# NUC400_v1 register map
File version: 1.0
Registers are 32-bit, read-write, reset 0x0 unless marked. A register's access mark holds for its fields unless they carry their own. Offsets are from the block's base; [hi:lo] are bit positions; {n}, {i} and the like mark numbered series; 'fields as' and 'values as' point back to an identical list.

## CRYP — CRYPTO Register Map
Base 0x50080000
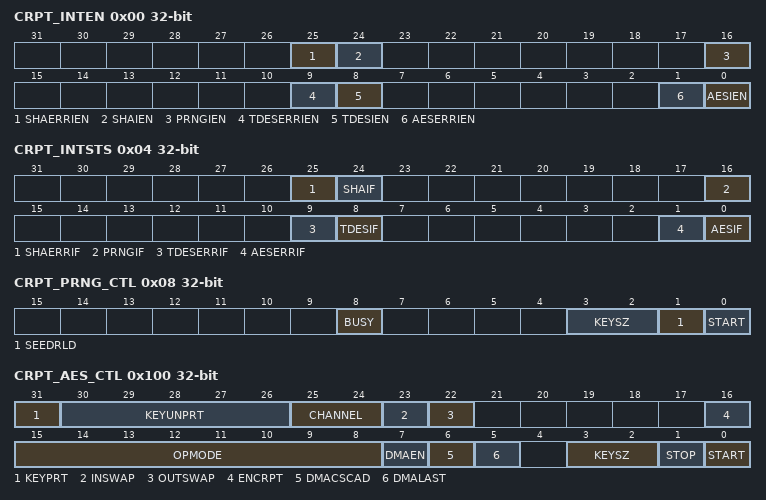
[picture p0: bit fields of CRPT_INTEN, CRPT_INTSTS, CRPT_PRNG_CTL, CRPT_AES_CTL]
0x00 CRPT_INTEN — Crypto Interrupt Enable Control Register
  [25] SHAERRIEN — SHA Error Interrupt Enable Bit
    0=SHA error interrupt flag Disabled; 1=SHA error interrupt flag Enabled
  [24] SHAIEN — SHA Interrupt Enable Bit. In DMA mode, an interrupt will be triggered when amount of data set in SHA _DMA_CNT is fed into the SHA engine. In Non-DMA mode, an interrupt will be triggered when the SHA engine finishes the operation.
    0=SHA interrupt Disabled; 1=SHA interrupt Enabled
  [16] PRNGIEN — PRNG Interrupt Enable Bit
    0=PRNG interrupt Disabled; 1=PRNG interrupt Enabled
  [9] TDESERRIEN — TDES/DES Error Flag Enable Bit
    0=TDES/DES error interrupt flag Disabled; 1=TDES/DES error interrupt flag Enabled
  [8] TDESIEN — TDES/DES Interrupt Enable Bit. In DMA mode, an interrupt will be triggered when amount of data set in TDES_DMA_CNT is fed into the TDES engine. In Non-DMA mode, an interrupt will be triggered when the TDES engine finishes the operation.
    0=TDES/DES interrupt Disabled; 1=TDES/DES interrupt Enabled
  [1] AESERRIEN — AES Error Flag Enable Bit
    0=AES error interrupt flag Disabled; 1=AES error interrupt flag Enabled
  [0] AESIEN — AES Interrupt Enable Bit. In DMA mode, an interrupt will be triggered when amount of data set in AES_DMA_CNT is fed into the AES engine. In Non-DMA mode, an interrupt will be triggered when the AES engine finishes the operation.
    0=AES interrupt Disabled; 1=AES interrupt Enabled
0x04 CRPT_INTSTS — Crypto Interrupt Flag
  [25] SHAERRIF — SHA Error Flag. This register includes operating and setting error. The detail flag is shown in SHA _FLAG register. This bit is cleared by writing 1, and it has no effect by writing 0.
    0=No SHA error; 1=SHA error interrupt
  [24] SHAIF — SHA Finish Interrupt Flag. This bit is cleared by writing 1, and it has no effect by writing 0.
    0=No SHA interrupt; 1=SHA operation done interrupt
  [16] PRNGIF — PRNG Finish Interrupt Flag. This bit is cleared by writing 1, and it has no effect by writing 0.
    0=No PRNG interrupt; 1=PRNG key generation done interrupt
  [9] TDESERRIF — TDES/DES Error Flag. This bit includes the operating and setting error. The detailed flag is shown in the TDES _FLAG register. This includes operating and setting error. This bit is cleared by writing 1, and it has no effect by writing 0.
    0=No TDES/DES error; 1=TDES/DES encryption/decryption error interrupt
  [8] TDESIF — TDES/DES Finish Interrupt Flag. This bit is cleared by writing 1, and it has no effect by writing 0.
    0=No TDES/DES interrupt; 1=TDES/DES encryption/decryption done interrupt
  [1] AESERRIF — AES Error Flag. This bit is cleared by writing 1, and it has no effect by writing 0.
    0=No AES error; 1=AES encryption/decryption done interrupt
  [0] AESIF — AES Finish Interrupt Flag. This bit is cleared by writing 1, and it has no effect by writing 0.
    0=No AES interrupt; 1=AES encryption/decryption done interrupt
0x08 CRPT_PRNG_CTL — PRNG Control Register
  [8] BUSY ro — PRNG Busy (Read Only)
    0=PRNG engine is idle; 1=Indicate that the PRNG engine is generating CRPT_PRNG_KEYx
  [3:2] KEYSZ — PRNG Generate Key Size
    0=64 bits; 1=128 bits; 2=192 bits; 3=256 bits
  [1] SEEDRLD — Reload New Seed For PRNG Engine
    0=Generating key based on the current seed; 1=Reload new seed
  [0] START — Start PRNG Engine
    0=Stop PRNG engine; 1=Generate new key and store the new key to register CRPT_PRNG_KEYx , which will be cleared when the new key is generated
0x0C CRPT_PRNG_SEED wo reset not defined — Seed for PRNG
  [31:0] SEED — Seed For PRNG (Write Only). The bits store the seed for PRNG engine.
{0x10+4i} CRPT_PRNG_KEY{i} ro reset not defined (i=0..7) — PRNG Generated Key{i}
  [31:0] KEYx — Store PRNG Generated Key (Read Only). The bits store the key that is generated by PRNG.
{0x50+4i} CRPT_AES_FDBCK{i} ro (i=0..3) — AES Engine Output Feedback Data After Cryptographic Operation
  [31:0] FDBCK — AES Feedback Information. The feedback value is 128 bits in size. The AES engine uses the data from CRPT_AES_FDBCKx as the data inputted to CRPT_AESn_IVx for the next block in DMA cascade mode. The AES engine outputs feedback information for IV in the next block's operation. Software can use this feedback information to implement more than four DMA channels. Software can store that feedback value temporarily. After switching back, fill the stored feedback value to this register in the same channel operation, and then continue the operation with the original setting.
0x60 CRPT_TDES_FDBCKH ro — TDES/DES Engine Output Feedback High Word Data After Cryptographic Operation
  [31:0] FDBCK — TDES/DES Feedback. The feedback value is 64 bits in size. The TDES/DES engine uses the data from {CRPT_TDES_FDBCKH, CRPT_TDES_FDBCKL} as the data inputted to {CRPT_TDESn_IVH, CRPT_TDESn_IVL} for the next block in DMA cascade mode. The feedback register is for CBC, CFB, and OFB mode. TDES/DES engine outputs feedback information for IV in the next block's operation. Software can use this feedback information to implement more than four DMA channels. Software can store that feedback value temporarily. After switching back, fill the stored feedback value to this register in the same channel operation. Then can continue the operation with the original setting.
0x64 CRPT_TDES_FDBCKL ro — TDES/DES Engine Output Feedback Low Word Data After Cryptographic Operation
  fields as CRPT_TDES_FDBCKH
0x100 CRPT_AES_CTL — AES Control Register
  [31] KEYPRT — Protect Key. Read as a flag to reflect KEYPRT.
    0=No effect; 1=Protect the content of the AES key from reading. The return value for reading CRPT_AESn_KEYx is not the content of the registers CRPT_AESn_KEYx. Once it is set, it can be cleared by asserting KEYUNPRT. And the key content would be cleared as well
  [30:26] KEYUNPRT — Unprotect Key. Writing 0 to CRPT_AES_CTL [31] and "10110" to CRPT_AES_CTL [30:26] is to unprotect the AES key. The KEYUNPRT can be read and written. When it is written as the AES engine is operating, BUSY flag is 1, there would be no effect on KEYUNPRT.
  [25:24] CHANNEL — AES Engine Working Channel
    {v}=Current control register setting is for channel {v} (v=0..3)
  [23] INSWAP — AES Engine Input Data Swap
    0=Keep the original order; 1=The order that CPU feeds data to the accelerator will be changed from {byte3, byte2, byte1, byte0} to {byte0, byte1, byte2, byte3}
  [22] OUTSWAP — AES Engine Output Data Swap
    0=Keep the original order; 1=The order that CPU outputs data from the accelerator will be changed from {byte3, byte2, byte1, byte0} to {byte0, byte1, byte2, byte3}
  [16] ENCRPT — AES Encryption/Decryption
    0=AES engine executes decryption operation; 1=AES engine executes encryption operation
  [15:8] OPMODE — AES Engine Operation Modes
    0=ECB (Electronic Codebook Mode) 0x01 = CBC (Cipher Block Chaining Mode); 2=CFB (Cipher Feedback Mode); 3=OFB (Output Feedback Mode); 4=CTR (Counter Mode); 16=CBC-CS1 (CBC Ciphertext-Stealing 1 Mode); 17=CBC-CS2 (CBC Ciphertext-Stealing 2 Mode); 18=CBC-CS3 (CBC Ciphertext-Stealing 3 Mode)
  [7] DMAEN — AES Engine DMA Enable Bit. The AES engine operates in DMA mode, and data movement from/to the engine is done by DMA logic.
    0=AES DMA engine Disabled; 1=AES DMA engine Enabled
  [6] DMACSCAD — AES Engine DMA With Cascade Mode
    0=DMA cascade function Disabled; 1=In DMA cascade mode, software can update DMA source address register, destination address register, and byte count register during a cascade operation, without finishing the accelerator operation
  [5] DMALAST — AES Last Block. In DMA mode, this bit must be set as beginning the last DMA cascade round. In Non-DMA mode, this bit must be set when feeding in the last block of data in ECB, CBC, CTR, OFB, and CFB mode, and feeding in the (last-1) block of data at CBC-CS1, CBC-CS2, and CBC-CS3 mode. This bit is always 0 when it's read back. Must be written again once START is triggered.
  [3:2] KEYSZ — AES Key Size. This bit defines three different key size for AES operation. If the AES accelerator is operating and the corresponding flag BUSY is 1, updating this register has no effect.
  [1] STOP — AES Engine Stop. Note: This bit is always 0 when it's read back.
    0=No effect; 1=Stop AES engine
  [0] START — AES Engine Start. Note: This bit is always 0 when it's read back.
    0=No effect; 1=Start AES engine. BUSY flag will be set
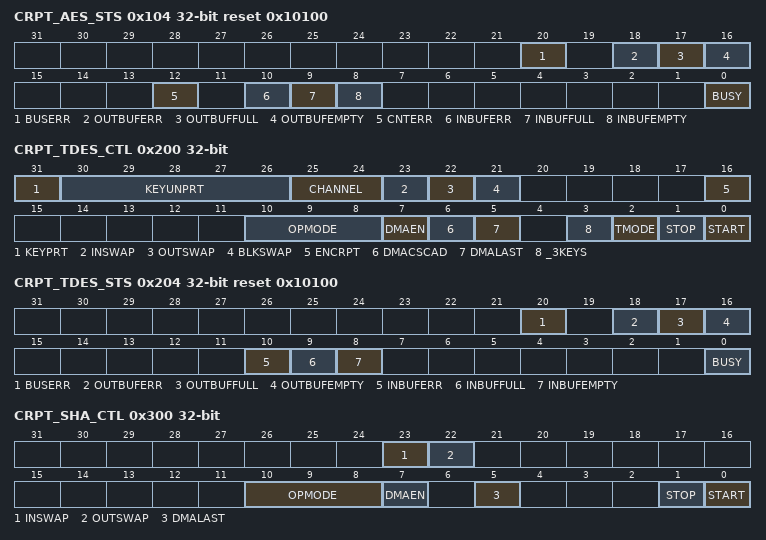
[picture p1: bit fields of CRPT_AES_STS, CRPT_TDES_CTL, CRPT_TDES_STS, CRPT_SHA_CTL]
0x104 CRPT_AES_STS ro reset 0x10100 — AES Engine Flag
  [20] BUSERR — AES DMA Access Bus Error Flag
    0=No error; 1=Bus error will stop DMA operation and AES engine
  [18] OUTBUFERR — AES Out Buffer Error Flag
    0=No error; 1=Error happens during getting the result from AES engine
  [17] OUTBUFFULL — AES Out Buffer Full Flag
    0=AES output buffer is not full; 1=AES output buffer is full, and software needs to get data from AES_DATA_OUT. Otherwise, the AES engine will be pending since the output buffer is full
  [16] OUTBUFEMPTY — AES Out Buffer Empty
    0=AES output buffer is not empty. There are some valid data kept in output buffer; 1=AES output buffer is empty. Software cannot get data from AES_DATA_OUT. Otherwise, the flag OUTBUFERR will be set to 1 since the output buffer is empty
  [12] CNTERR — AES_CNT Setting Error
    0=No error in AES_CNT setting; 1=AES_CNT is not a multiply of 16 in ECB, CBC, CFB, OFB, and CTR mode
  [10] INBUFERR — AES Input Buffer Error Flag
    0=No error; 1=Error happens during feeding data to the AES engine
  [9] INBUFFULL — AES Input Buffer Full Flag
    0=AES input buffer is not full. Software can feed the data into the AES engine; 1=AES input buffer is full. Software cannot feed data to the AES engine. Otherwise, the flag INBUFERR will be set to 1
  [8] INBUFEMPTY — AES Input Buffer Empty
    0=There are some data in input buffer waiting for the AES engine to process; 1=AES input buffer is empty. Software needs to feed data to the AES engine. Otherwise, the AES engine will be pending to wait for input data
  [0] BUSY — AES Engine Busy
    0=The AES engine is idle or finished; 1=The AES engine is under processing
0x108 CRPT_AES_DATIN — AES Engine Data Input Port Register
  [31:0] DATIN — AES Engine Input Port. CPU feeds data to AES engine through this port by checking CRPT_AES_STS. Feed data as INBUFFULL is 0.
0x10C CRPT_AES_DATOUT ro — AES Engine Data Output Port Register
  [31:0] DATOUT — AES Engine Output Port. CPU gets results from the AES engine through this port by checking CRPT_AES_STS. Get data as OUTBUFEMPTY is 0.
{0x110+4i} CRPT_AES0_KEY{i} (i=0..7) — AES Key Word {i} Register for Channel 0
  [31:0] KEY — CRPT_AESn_KEYx. The KEY keeps the security key for AES operation. The security key for AES accelerator can be 128, 192, or 256 bits and four, six, or eight 32-bit registers are to store each security key. {CRPT_AESn_KEY3, CRPT_AESn_KEY2, CRPT_AESn_KEY1, CRPT_AESn_KEY0} stores the 128-bit security key for AES operation. {CRPT_AESn_KEY5, CRPT_AESn_KEY4, CRPT_AESn_KEY3, CRPT_AESn_KEY2, CRPT_AESn_KEY1, CRPT_AESn_KEY0} stores the 192-bit security key for AES operation. {CRPT_AESn_KEY7, CRPT_AESn_KEY6, CRPT_AESn_KEY5, CRPT_AESn_KEY4, CRPT_AESn_KEY3, CRPT_AESn_KEY2, CRPT_AESn_KEY1, CRPT_AESn_KEY0} stores the 256-bit security key for AES operation.
{0x130+0x3C*i} CRPT_AES{i}_IV0 (i=0..3) — AES Initial Vector Word 0 Register for Channel {i}
  [31:0] IV — CRPT_AESn_IVx. Four initial vectors (CRPT_AESn_IV0, CRPT_AESn_IV1, CRPT_AESn_IV2, and CRPT_AESn_IV3) are for AES operating in CBC, CFB, and OFB mode. Four registers (CRPT_AESn_IV0, CRPT_AESn_IV1, CRPT_AESn_IV2, and CRPT_AESn_IV3) act as Nonce counter when the AES engine is operating in CTR mode.
{0x134+0x3C*i} CRPT_AES{i}_IV1 (i=0..3) — AES Initial Vector Word 1 Register for Channel {i}
  fields as CRPT_AES0_IV0
{0x138+0x3C*i} CRPT_AES{i}_IV2 (i=0..3) — AES Initial Vector Word 2 Register for Channel {i}
  fields as CRPT_AES0_IV0
{0x13C+0x3C*i} CRPT_AES{i}_IV3 (i=0..3) — AES Initial Vector Word 3 Register for Channel {i}
  fields as CRPT_AES0_IV0
{0x140+0x3C*i} CRPT_AES{i}_SADDR (i=0..3) — AES DMA Source Address Register for Channel {i}
  [31:0] SADDR — AES DMA Source Address. The AES accelerator supports DMA function to transfer the plain text between system memory and embedded FIFO. The SADDR keeps the source address of the data buffer where the source text is stored. Based on the source address, the AES accelerator can read the plain text from system memory and do AES operation. The start of source address should be located at word boundary. In other words, bit 1 and 0 of SADDR are ignored. SADDR can be read and written. Writing to SADDR while the AES accelerator is operating doesn't affect the current AES operation. But the value of SADDR will be updated later on. Consequently, software can prepare the DMA source address for the next AES operation. In DMA mode, software can update the next CRPT_AESn_SADDR before triggering START. The value of CRPT_AESn_SADDR and CRPT_AESn_DADDR can be the same.
{0x144+0x3C*i} CRPT_AES{i}_DADDR (i=0..3) — AES DMA Destination Address Register for Channel {i}
  [31:0] DADDR — AES DMA Destination Address. The AES accelerator supports DMA function to transfer the cipher text between system memory and embedded FIFO. The DADDR keeps the destination address of the data buffer where the engine output's text will be stored. Based on the destination address, the AES accelerator can write the cipher text back to system memory after the AES operation is finished. The start of destination address should be located at word boundary. In other words, bit 1 and 0 of DADDR are ignored. DADDR can be read and written. Writing to DADDR while the AES accelerator is operating doesn't affect the current AES operation. But the value of DADDR will be updated later on. Consequently, software can prepare the destination address for the next AES operation. In DMA mode, software can update the next CRPT_AESn_DADDR before triggering START. The value of CRPT_AESn_SADDR and CRPT_AESn_DADDR can be the same.
{0x148+0x3C*i} CRPT_AES{i}_CNT (i=0..3) — AES Byte Count Register for Channel {i}
  [31:0] CNT — AES Byte Count. The CRPT_AESn_CNT keeps the byte count of source text that is for the AES engine operating in DMA mode. The CRPT_AESn_CNT is 32-bit and the maximum of byte count is 4G bytes. CRPT_AESn_CNT can be read and written. Writing to CRPT_AESn_CNT while the AES accelerator is operating doesn't affect the current AES operation. But the value of CRPT_AESn_CNT will be updated later on. Consequently, software can prepare the byte count of data for the next AES operation. According to CBC-CS1, CBC-CS2, and CBC-CS3 standard, the count of operation data must be at least one block. Operations that are less than one block will output unexpected result. In Non-DMA ECB, CBC, CFB, OFB, and CTR mode, CRPT_AESn_CNT must be set as byte count for the last block of data before feeding in the last block of data. In Non-DMA CBC-CS1, CBC-CS2, and CBC-CS3 mode, CRPT_AESn_CNT must be set as byte count for the last two blocks of data before feeding in the last two blocks of data.
{0x14C+4i} CRPT_AES1_KEY{i} (i=0..7) — AES Key Word {i} Register for Channel 1
  fields as CRPT_AES0_KEY0
{0x188+4i} CRPT_AES2_KEY{i} (i=0..7) — AES Key Word {i} Register for Channel 2
  fields as CRPT_AES0_KEY0
{0x1C4+4i} CRPT_AES3_KEY{i} (i=0..7) — AES Key Word {i} Register for Channel 3
  fields as CRPT_AES0_KEY0
0x200 CRPT_TDES_CTL — TDES/DES Control Register
  [31] KEYPRT — Protect Key. Read as a flag to reflect KEYPRT.
    0=No effect; 1=This bit is to protect the content of TDES key from reading. The return value for reading CRPT_ TDESn_KEYxH/L is not the content in the registers CRPT_ TDESn_KEYxH/L. Once it is set, it can be cleared by asserting KEYUNPRT. The key content would be cleared as well
  [30:26] KEYUNPRT — Unprotect Key. Writing 0 to CRPT_TDES_CTL [31] and "10110" to CRPT_TDES_CTL [30:26] is to unprotect TDES key. The KEYUNPRT can be read and written. When it is written as the TDES engine is operating, BUSY flag is 1, there would be no effect on KEYUNPRT.
  [25:24] CHANNEL — TDES/DES Engine Working Channel
    values as CRPT_AES_CTL.CHANNEL
  [23] INSWAP — TDES/DES Engine Input Data Swap
    values as CRPT_AES_CTL.INSWAP
  [22] OUTSWAP — TDES/DES Engine Output Data Swap
    values as CRPT_AES_CTL.OUTSWAP
  [21] BLKSWAP — TDES/DES Engine Block Double Word Endian Swap
    0=Keep the original order, e.g. {WORD_H, WORD_L}; 1=When this bit is set to 1, the TDES engine would exchange high and low word in the sequence {WORD_L, WORD_H}
  [16] ENCRPT — TDES/DES Encryption/Decryption
    0=TDES engine executes decryption operation; 1=TDES engine executes encryption operation
  [10:8] OPMODE — TDES/DES Engine Operation Mode
    0=ECB (Electronic Codebook Mode); 1=CBC (Cipher Block Chaining Mode); 2=CFB (Cipher Feedback Mode); 3=OFB (Output Feedback Mode); 4=CTR (Counter Mode)
  [7] DMAEN — TDES/DES Engine DMA Enable Bit. TDES engine operates in DMA mode, and data movement from/to the engine is done by DMA logic.
    0=TDES_DMA engine Disabled; 1=TDES_DMA engine Enabled
  [6] DMACSCAD — TDES/DES Engine DMA With Cascade Mode
    0=DMA cascade function Disabled; 1=In DMA Cascade mode, software can update DMA source address register, destination address register, and byte count register during a cascade operation, without finishing the accelerator operation
  [5] DMALAST — TDES/DES Engine Start For The Last Block. In DMA mode, this bit must be set as beginning the last DMA cascade round. In Non-DMA mode, this bit must be set as feeding in last block of data.
  [3] _3KEYS — TDES/DES Key Number
    0=Select KEY1 and KEY2 in TDES/DES engine; 1=Triple keys in TDES/DES engine Enabled
  [2] TMODE — TDES/DES Engine Operating Mode
    0=Set DES mode for TDES/DES engine; 1=Set Triple DES mode for TDES/DES engine
  [1] STOP — TDES/DES Engine Stop. Note: The bit is always 0 when it's read back.
    0=No effect; 1=Stop TDES/DES engine
  [0] START — TDES/DES Engine Start. Note: The bit is always 0 when it's read back.
    0=No effect; 1=Start TDES/DES engine. The flag BUSY would be set
0x204 CRPT_TDES_STS ro reset 0x10100 — TDES/DES Engine Flag
  [20] BUSERR — TDES/DES DMA Access Bus Error Flag
    0=No error; 1=Bus error will stop DMA operation and TDES/DES engine
  [18] OUTBUFERR — TDES/DES Out Buffer Error Flag
    0=No error; 1=Error happens during getting test result from TDES/DES engine
  [17] OUTBUFFULL — TDES/DES Output Buffer Full Flag
    0=TDES/DES output buffer is not full; 1=TDES/DES output buffer is full, and software needs to get data from TDES_DATA_OUT. Otherwise, the TDES/DES engine will be pending since output buffer is full
  [16] OUTBUFEMPTY — TDES/DES Output Buffer Empty Flag
    0=TDES/DES output buffer is not empty. There are some valid data kept in output buffer; 1=TDES/DES output buffer is empty, Software cannot get data from TDES_DATA_OUT. Otherwise the flag OUTBUFERR will be set to 1, since output buffer is empty
  [10] INBUFERR — TDES/DES In Buffer Error Flag
    0=No error; 1=Error happens during feeding data to the TDES/DES engine
  [9] INBUFFULL — TDES/DES In Buffer Full Flag
    0=TDES/DES input buffer is not full. Software can feed the data into the TDES/DES engine; 1=TDES input buffer is full. Software cannot feed data to the TDES/DES engine. Otherwise, the flag INBUFERR will be set to 1
  [8] INBUFEMPTY — TDES/DES In Buffer Empty
    0=There are some data in input buffer waiting for the TDES/DES engine to process; 1=TDES/DES input buffer is empty. Software needs to feed data to the TDES/DES engine. Otherwise, the TDES/DES engine will be pending to wait for input data
  [0] BUSY — TDES/DES Engine Busy
    0=TDES/DES engine is idle or finished; 1=TDES/DES engine is under processing
{0x208+0x40*i} CRPT_TDES{i}_KEY1H (i=0..3) — TDES/DES Key 1 High Word Register for Channel {i}
  [31:0] KEYH_KEYL — TDES/DES Key X High/Low Word. The key registers for TDES/DES algorithm calculation. The security key for the TDES/DES accelerator is 64 bits. Thus, it needs two 32-bit registers to store a security key. The register CRPT_TDESn_KEYxH is used to keep the bit [63:32] of security key for the TDES/DES operation, while the register CRPT_TDESn_KEYxL is used to keep the bit [31:0].
{0x20C+0x40*i} CRPT_TDES{i}_KEY1L (i=0..3) — TDES/DES Key 1 Low Word Register for Channel {i}
  fields as CRPT_TDES0_KEY1H
{0x210+0x40*i} CRPT_TDES{i}_KEY2H (i=0..3) — TDES Key 2 High Word Register for Channel {i}
  fields as CRPT_TDES0_KEY1H
{0x214+0x40*i} CRPT_TDES{i}_KEY2L (i=0..3) — TDES Key 2 Low Word Register for Channel {i}
  fields as CRPT_TDES0_KEY1H
{0x218+0x40*i} CRPT_TDES{i}_KEY3H (i=0..3) — TDES Key 3 High Word Register for Channel {i}
  fields as CRPT_TDES0_KEY1H
{0x21C+0x40*i} CRPT_TDES{i}_KEY3L (i=0..3) — TDES Key 3 Low Word Register for Channel {i}
  fields as CRPT_TDES0_KEY1H
{0x220+0x40*i} CRPT_TDES{i}_IVH (i=0..3) — TDES/DES Initial Vector High Word Register for Channel {i}
  [31:0] IVH_IVL — TDES/DES Initial Vector High/Low Word. Initial vector (IV) is for TDES/DES engine in CBC, CFB, and OFB mode. IV is Nonce counter for TDES/DES engine in CTR mode.
{0x224+0x40*i} CRPT_TDES{i}_IVL (i=0..3) — TDES/DES Initial Vector Low Word Register for Channel {i}
  fields as CRPT_TDES0_IVH
{0x228+0x40*i} CRPT_TDES{i}_SADDR (i=0..3) — TDES/DES DMA Source Address Register for Channel {i}
  [31:0] SADDR — TDES/DES DMA Source Address. The TDES/DES accelerator supports DMA function to transfer the plain text between system memory and embedded FIFO. The CRPT_TDESn_SADDR keeps the source address of the data buffer where the source text is stored. Based on the source address, the TDES/DES accelerator can read the plain text from system memory and do TDES/DES operation. The start of source address should be located at word boundary. In other words, bit 1 and 0 of CRPT_TDESn_SADDR are ignored. TDES_SADR can be read and written. Writing to TDES_SADR while the TDES/DES accelerator is operating doesn't affect the current TDES/DES operation. But the value of CRPT_TDESn_SADDR will be updated later on. Consequently, software can prepare the DMA source address for the next TDES/DES operation. In DMA mode, software can update the next CRPT_TDESn_SADDR before triggering START. CRPT_TDESn_SADDR and CRPT_TDESn_DADDR can be the same in the value.
{0x22C+0x40*i} CRPT_TDES{i}_DADDR (i=0..3) — TDES/DES DMA Destination Address Register for Channel {i}
  [31:0] DADDR — TDES/DES DMA Destination Address. The TDES/DES accelerator supports DMA function to transfer the cipher text between system memory and embedded FIFO. The CRPT_TDESn_DADDR keeps the destination address of the data buffer where the engine output's text will be stored. Based on the destination address, the TDES/DES accelerator can write the cipher text back to system memory after the TDES/DES operation is finished. The start of destination address should be located at word boundary. In other words, bit 1 and 0 of CRPT_TDESn_DADDR are ignored. TDES_DADR can be read and written. Writing to TDES_DADR while the TDES/DES accelerator is operating doesn't affect the current TDES/DES operation. But the value of CRPT_TDESn_DADDR will be updated later on. Consequently, software can prepare the destination address for the next TDES/DES operation. In DMA mode, software can update the next CRPT_TDESn_DADDR before triggering START. CRPT_TDESn_SADDR and CRPT_TDESn_DADDR can be the same in the value.
{0x230+0x40*i} CRPT_TDES{i}_CNT (i=0..3) — TDES/DES Byte Count Register for Channel {i}
  [31:0] CNT — TDES/DES Byte Count. The CRPT_TDESn_CNT keeps the byte count of source text that is for the TDES/DES engine operating in DMA mode. The CRPT_TDESn_CNT is 32-bit and the maximum of byte count is 4G bytes. CRPT_TDESn_CNT can be read and written. Writing to CRPT_TDESn_CNT while the TDES/DES accelerator is operating doesn't affect the current TDES/DES operation. But the value of CRPT_TDESn_CNT will be updated later on. Consequently, software can prepare the byte count of data for the next TDES /DES operation. In Non-DMA ECB, CBC, CFB, OFB, and CTR mode, TDES_CNT must be set as byte count for the last block of data before feeding in the last block of data.
0x234 CRPT_TDES_DATIN — TDES/DES Engine Input Data Word Register
  [31:0] DATIN — TDES/DES Engine Input Port. CPU feeds data to TDES/DES engine through this port by checking CRPT_TDES_STS. Feed data as INBUFFULL is 0.
0x238 CRPT_TDES_DATOUT ro — TDES/DES Engine Output Data Word Register
  [31:0] DATOUT — TDES/DES Engine Output Port. CPU gets result from the TDES/DES engine through this port by checking CRPT_TDES_STS. Get data as OUTBUFEMPTY is 0.
0x300 CRPT_SHA_CTL — SHA Control Register
  [23] INSWAP — SHA Engine Input Data Swap
    values as CRPT_AES_CTL.INSWAP
  [22] OUTSWAP — SHA Engine Output Data Swap
    values as CRPT_AES_CTL.INSWAP
  [10:8] OPMODE — SHA Engine Operation Modes. Note: These bits can be read and written, but writing to them wouldn't take effect as BUSY is 1.
    0=SHA160; 4=SHA256; 5=SHA224
  [7] DMAEN — SHA Engine DMA Enable Bit. The SHA engine operates in DMA mode, and data movement from/to the engine is done by DMA logic.
    0=SHA_DMA engine Disabled; 1=SHA_DMA engine Enabled
  [5] DMALAST — SHA Last Block. In DMA mode, this bit must be set as beginning the last DMA cascade round. In Non-DMA mode, this bit must be set as feeding in last byte of data.
  [1] STOP — SHA Engine Stop. Note: This bit is always 0 when it's read back.
    0=No effect; 1=Stop SHA engine
  [0] START — SHA Engine Start. Note: This bit is always 0 when it's read back.
    0=No effect; 1=Start SHA engine. BUSY flag will be set
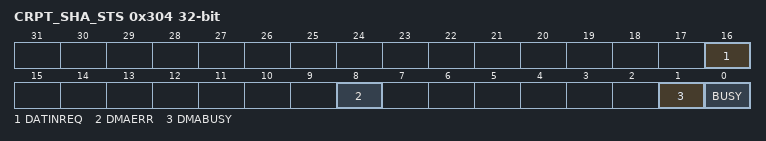
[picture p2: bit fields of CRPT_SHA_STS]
0x304 CRPT_SHA_STS ro — SHA Status Flag
  [16] DATINREQ — SHA Non-DMA Mode Data Input Request
    0=No effect; 1=Request SHA Non-DMA mode data input
  [8] DMAERR — SHA Engine DMA Error Flag
    0=Show the SHA engine access normal; 1=Show the SHA engine access error
  [1] DMABUSY — SHA Engine DMA Busy Flag
    0=SHA DMA engine is idle or finished; 1=SHA DMA engine is busy
  [0] BUSY — SHA Engine Busy
    0=SHA engine is idle or finished; 1=SHA engine is busy
{0x308+4i} CRPT_SHA_DGST{i} ro (i=0..7) — SHA Digest Message {i}
  [31:0] DGST — SHA Digest Message Word. For SHA-160, the digest is stored in CRPT_SHA_DGST0 ~ CRPT_SHA_DGST4. For SHA-224, the digest is stored in CRPT_SHA_DGST0 ~ CRPT_SHA_DGST6. For SHA-256, the digest is stored in CRPT_SHA_DGST0 ~ CRPT_SHA_DGST7.
0x348 CRPT_SHA_KEYCNT — SHA Key Byte Count Register
  [31:0] KEYCNT — SHA Key Byte Count. The CRPT_SHA_KEYCNT keeps the byte count of key that SHA engine operates. The register is 32-bit and the maximum byte count is 4G bytes. It can be read and written. Writing to the register CRPT_SHA_KEYCNT as the SHA accelerator operating doesn't affect the current SHA operation. But the value of CRPT_SHA_KEYCNT will be updated later on. Consequently, software can prepare the key count for the next SHA operation.
0x34C CRPT_SHA_SADDR — SHA DMA Source Address Register
  [31:0] SADDR — SHA DMA Source Address. The SHA accelerator supports DMA function to transfer the plain text between system memory and embedded FIFO. The CRPT_SHA_SADDR keeps the source address of the data buffer where the source text is stored. Based on the source address, the SHA accelerator can read the plain text from system memory and do SHA operation. The start of source address should be located at word boundary. In other words, bit 1 and 0 of CRPT_SHA_SADDR are ignored. CRPT_SHA_SADDR can be read and written. Writing to CRPT_SHA_SADDR while the SHA accelerator is operating doesn't affect the current SHA operation. But the value of CRPT_SHA_SADDR will be updated later on. Consequently, software can prepare the DMA source address for the next SHA operation. In DMA mode, software can update the next TDES_SADR before triggering START. CRPT_SHA_SADDR and CRPT_SHA_DADDR can be the same in the value.
0x350 CRPT_SHA_DMACNT — SHA Byte Count Register
  [31:0] DMACNT — SHA Operation Byte Count. The CRPT_SHA_DMACNT keeps the byte count of source text that is for the SHA engine operating in DMA mode. The CRPT_SHA_DMACNT is 32-bit and the maximum of byte count is 4G bytes. CRPT_SHA_DMACNT can be read and written. Writing to CRPT_SHA_DMACNT while the SHA accelerator is operating doesn't affect the current SHA operation. But the value of CRPT_SHA_DMACNT will be updated later on. Consequently, software can prepare the byte count of data for the next SHA operation. In Non-DMA mode, CRPT_SHA_DMACNT must be set as the byte count of the last block before feeding in the last block of data.
0x354 CRPT_SHA_DATIN — SHA Engine Non-dMA Mode Data Input Port Register
  [31:0] DATIN — SHA Engine Input Port. CPU feeds data to SHA engine through this port by checking CRPT_SHA_STS. Feed data as DATINREQ is 1.
